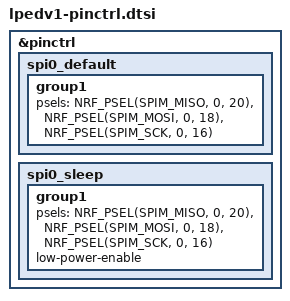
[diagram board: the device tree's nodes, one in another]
&pinctrl {
	spi0_default: spi0_default {
		group1 {
			psels = <NRF_PSEL(SPIM_MISO,	0, 	20)>,
					<NRF_PSEL(SPIM_MOSI, 	0, 	18)>,
					<NRF_PSEL(SPIM_SCK, 	0, 	16)>;
		};
	};

	spi0_sleep: spi0_sleep {
		group1 {
			psels = <NRF_PSEL(SPIM_MISO,	0, 	20)>,
					<NRF_PSEL(SPIM_MOSI, 	0, 	18)>,
					<NRF_PSEL(SPIM_SCK, 	0, 	16)>;
			low-power-enable;
		};
	};
};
